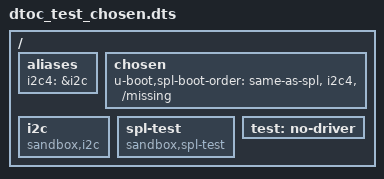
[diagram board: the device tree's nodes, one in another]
// SPDX-License-Identifier: GPL-2.0+
/*
 * Test device tree file for dtoc
 *
 * Copyright 2026 Simon Glass <sjg@chromium.org>
 */

/dts-v1/;

/ {
	#address-cells = <1>;
	#size-cells = <1>;

	aliases {
		i2c4 = &i2c;
	};

	chosen {
		u-boot,spl-boot-order = "same-as-spl", &i2c, "i2c4", &test,
			"/missing";
	};

	i2c: i2c {
		bootph-all;
		compatible = "sandbox,i2c";
	};

	spl-test {
		bootph-all;
		compatible = "sandbox,spl-test";
	};

	test: no-driver {
	};
};
